# MCU_MCAN0_MSGMEM_RAM register map
Vendor: Texas Instruments
Peripheral module from a debugger description file (folder J721S2).
Registers are 32-bit, read-write, reset 0x0 unless marked. A register's access mark holds for its fields unless they carry their own. Offsets are as the file gives them; lines under a group give offsets from that group; [hi:lo] are bit positions; {n}, {i} and the like mark numbered series; 'fields as' and 'values as' point back to an identical list; <NAME> marks a mode.

## MCU_MCAN0_MSGMEM_RAM
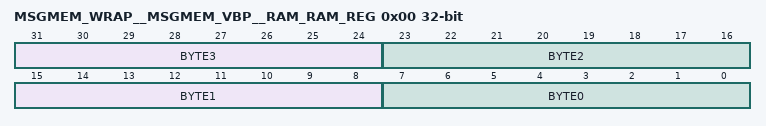
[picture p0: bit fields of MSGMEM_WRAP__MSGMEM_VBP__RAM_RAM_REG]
0x00 MSGMEM_WRAP__MSGMEM_VBP__RAM_RAM_REG — The RAM memory words provide memory mapped random access data storage.
  [31:24] BYTE3 — This is the MS byte
  [23:16] BYTE2 — This is the UM byte
  [15:8] BYTE1 — This is the LM byte
  [7:0] BYTE0 — This is the LS byte
